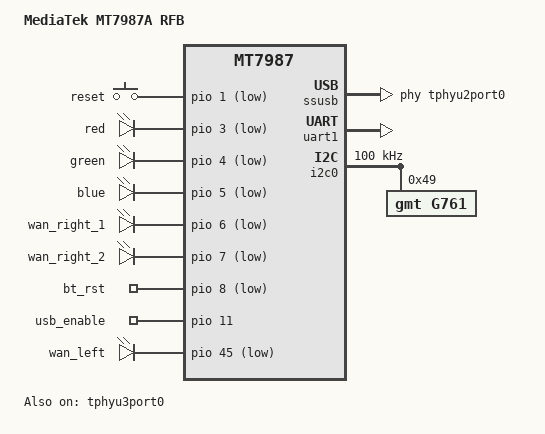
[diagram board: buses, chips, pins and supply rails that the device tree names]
// SPDX-License-Identifier: (GPL-2.0 OR MIT)
/*
 * Copyright (C) 2025 MediaTek Inc.
 * Author: Sam.Shih <sam.shih@mediatek.com>
 */

/dts-v1/;
#include "mt7987a.dtsi"
#include <dt-bindings/input/input.h>

/* MT7987A RFB DTS for DT overlay-based device tree */
/ {
	model = "MediaTek MT7987A RFB";
	compatible = "mediatek,mt7987a", "mediatek,mt7987";

	chosen {
		bootargs = "console=ttyS0,115200n1 loglevel=8  \
			    earlycon=uart8250,mmio32,0x11000000 \
			    pci=pcie_bus_perf ubi.block=0,firmware \
			    root=/dev/fit0 rootwait";
	};

	gpio-keys {
		compatible = "gpio-keys";

		reset {
			label = "reset";
			linux,code = <KEY_RESTART>;
			gpios = <&pio 1 GPIO_ACTIVE_LOW>;
			debounce-interval = <10>;
		};
	};

	gpio-leds {
		compatible = "gpio-leds";
		led@3 {
			label = "red";
			gpios = <&pio 3 GPIO_ACTIVE_LOW>;
		};
		led@4 {
			label = "green";
			gpios = <&pio 4 GPIO_ACTIVE_LOW>;
			default-state = "on";
			linux,default-trigger = "default-on";
		};
		led@5 {
			label = "blue";
			gpios = <&pio 5 GPIO_ACTIVE_LOW>;
		};
		led@6 {
			label = "wan_right_1";
			gpios = <&pio 6 GPIO_ACTIVE_LOW>;
		};
		led@7 {
			label = "wan_right_2";
			gpios = <&pio 7 GPIO_ACTIVE_LOW>;
		};
		led@8 {
			label = "bt_rst";
			gpios = <&pio 8 GPIO_ACTIVE_LOW>;
		};
		led@11 {
			label = "usb_enable";
			gpios = <&pio 11 GPIO_ACTIVE_HIGH>;
			default-state = "on";
			linux,default-trigger = "default-on";
		};
		led@45 {
			label = "wan_left";
			gpios = <&pio 45 GPIO_ACTIVE_LOW>;
		};
	};
};

&hnat {
	mtketh-wan = "eth0";
	mtketh-lan = "eth1";
	mtketh-max-gmac = <2>;
};

&tphyu3port0 {
	status = "okay";
};

&ssusb {
	mediatek,u3p-dis-msk=<0>;

	phys = <&tphyu2port0 PHY_TYPE_USB2>,
	       <&tphyu3port0 PHY_TYPE_USB3>;
};

&uart1 {
	pinctrl-names = "default";
	pinctrl-0 = <&uart1_pins>;
	status = "okay";
};

&i2c0 {
	#address-cells = <1>;
	#size-cells = <0>;
	clock-frequency = <100000>;        /* set I2C to 100 kHz */

	g761@49 {
		compatible = "gmt,g761";
		reg = <0x49>;
		fan_gear_mode = <0>;
		fan_startv = <1>;
		pwm_polarity = <0>;
	};
};

&afe {
	status = "disabled";
};
